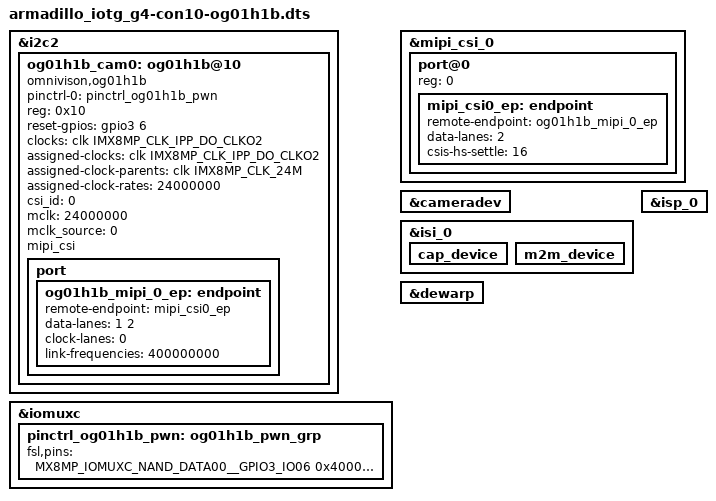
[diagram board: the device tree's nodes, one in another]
// SPDX-License-Identifier: (GPL-2.0 OR MIT)
/*
 * Copyright (C) 2025 Atmark Techno, Inc. All Rights Reserved.
 */

/dts-v1/;
/plugin/;

#include <dt-bindings/clock/imx8mp-clock.h>
#include <dt-bindings/gpio/gpio.h>
#include "imx8mp-pinfunc.h"

&i2c2 {
	#address-cells = <1>;
	#size-cells = <0>;

	og01h1b_cam0: og01h1b@10 {
		pinctrl-names = "default";
		pinctrl-0 = <&pinctrl_og01h1b_pwn>;

		compatible = "omnivison,og01h1b";
		reg = <0x10>;

		reset-gpios = <&gpio3 6 GPIO_ACTIVE_HIGH>;

		clocks = <&clk IMX8MP_CLK_IPP_DO_CLKO2>;
		clock-names = "csi_mclk";
		assigned-clocks = <&clk IMX8MP_CLK_IPP_DO_CLKO2>;
		assigned-clock-parents = <&clk IMX8MP_CLK_24M>;
		assigned-clock-rates = <24000000>;
		csi_id = <0>;
		mclk = <24000000>;
		mclk_source = <0>;
		mipi_csi;
		status = "okay";

		port {
			og01h1b_mipi_0_ep: endpoint {
				remote-endpoint = <&mipi_csi0_ep>;
				data-lanes = <1 2>;
				clock-lanes = <0>;
				link-frequencies = /bits/ 64 <400000000>;
			};
		};
	};
};

&iomuxc {
	pinctrl_og01h1b_pwn: og01h1b_pwn_grp {
		fsl,pins = <
			MX8MP_IOMUXC_NAND_DATA00__GPIO3_IO06	0x40000100
		>;
	};
};

&mipi_csi_0 {
	#address-cells = <1>;
	#size-cells = <0>;
	status = "okay";

	port@0 {
		reg = <0>;
		mipi_csi0_ep: endpoint {
			remote-endpoint = <&og01h1b_mipi_0_ep>;
			data-lanes = <2>;
			csis-hs-settle = <16>;
		};
	};
};

&cameradev {
	status = "okay";
};

&isi_0 {
	status = "okay";

	cap_device {
		status = "okay";
	};

	m2m_device {
		status = "okay";
	};
};

&isp_0 {
	status = "okay";
};

&dewarp {
	status = "okay";
};
